# RP2350 register map
Vendor: Raspberry Pi; File version: 0.1
CPU: CM33 r1p0, little endian, MPU, FPU, VTOR, 4 interrupt priority bits, 54 interrupts, 8 SAU regions
Registers are 32-bit, read-write, reset 0x0 unless marked. A register's access mark holds for its fields unless they carry their own. Offsets are from the block's base; [hi:lo] are bit positions; {n}, {i} and the like mark numbered series; 'fields as' and 'values as' point back to an identical list.

## TICKS
Base 0x40108000
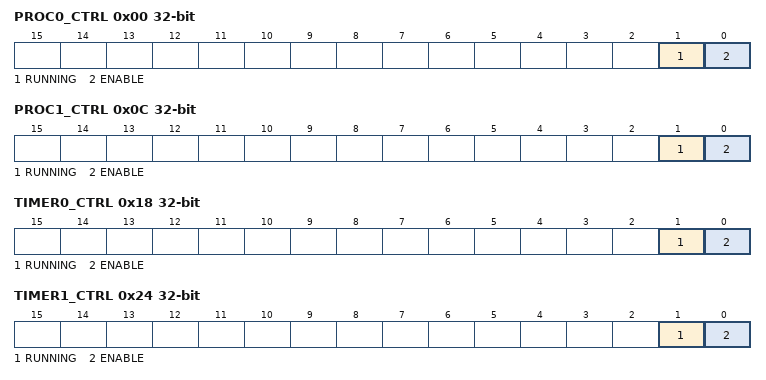
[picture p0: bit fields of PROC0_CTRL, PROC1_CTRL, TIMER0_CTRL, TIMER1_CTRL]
0x00 PROC0_CTRL access per field — Controls the tick generator
  [1] RUNNING ro — Is the tick generator running?
  [0] ENABLE rw — start / stop tick generation
0x04 PROC0_CYCLES
  [8:0] PROC0_CYCLES — Total number of clk_tick cycles before the next tick.
0x08 PROC0_COUNT ro
  [8:0] PROC0_COUNT — Count down timer: the remaining number clk_tick cycles before the next tick is generated.
0x0C PROC1_CTRL access per field — Controls the tick generator
  fields as PROC0_CTRL
0x10 PROC1_CYCLES
  [8:0] PROC1_CYCLES — Total number of clk_tick cycles before the next tick.
0x14 PROC1_COUNT ro
  [8:0] PROC1_COUNT — Count down timer: the remaining number clk_tick cycles before the next tick is generated.
0x18 TIMER0_CTRL access per field — Controls the tick generator
  fields as PROC0_CTRL
0x1C TIMER0_CYCLES
  [8:0] TIMER0_CYCLES — Total number of clk_tick cycles before the next tick.
0x20 TIMER0_COUNT ro
  [8:0] TIMER0_COUNT — Count down timer: the remaining number clk_tick cycles before the next tick is generated.
0x24 TIMER1_CTRL access per field — Controls the tick generator
  fields as PROC0_CTRL
0x28 TIMER1_CYCLES
  [8:0] TIMER1_CYCLES — Total number of clk_tick cycles before the next tick.
0x2C TIMER1_COUNT ro
  [8:0] TIMER1_COUNT — Count down timer: the remaining number clk_tick cycles before the next tick is generated.
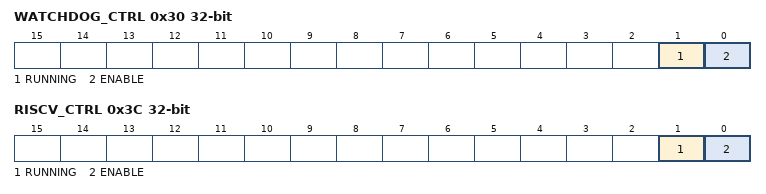
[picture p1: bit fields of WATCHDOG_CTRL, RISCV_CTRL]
0x30 WATCHDOG_CTRL access per field — Controls the tick generator
  fields as PROC0_CTRL
0x34 WATCHDOG_CYCLES
  [8:0] WATCHDOG_CYCLES — Total number of clk_tick cycles before the next tick.
0x38 WATCHDOG_COUNT ro
  [8:0] WATCHDOG_COUNT — Count down timer: the remaining number clk_tick cycles before the next tick is generated.
0x3C RISCV_CTRL access per field — Controls the tick generator
  fields as PROC0_CTRL
0x40 RISCV_CYCLES
  [8:0] RISCV_CYCLES — Total number of clk_tick cycles before the next tick.
0x44 RISCV_COUNT ro
  [8:0] RISCV_COUNT — Count down timer: the remaining number clk_tick cycles before the next tick is generated.

## GLITCH_DETECTOR — Glitch detector controls
Base 0x40158000
0x00 ARM reset 0x5BAD — Forcibly arm the glitch detectors, if they are not already armed by OTP. When armed, any individual detector trigger will cause a restart of the switched core power domain's power-on reset state machine. . Glitch detector triggers are recorded accumulatively in TRIG_STATUS. If the system is reset by a glitch detector trigger, this is recorded in POWMAN_CHIP_RESET. . This register is Secure read/write only.
  [15:0] ARM
    0x5BAD=no (Do not force the glitch detectors to be armed); 0=yes (Force the glitch detectors to be armed. (Any value other than ARM_NO counts as YES))
0x04 DISARM
  [15:0] DISARM — Forcibly disarm the glitch detectors, if they are armed by OTP. Ignored if ARM is YES. . This register is Secure read/write only.
    0=no (Do not disarm the glitch detectors. (Any value other than DISARM_YES counts as NO)); 0xDCAF=yes (Disarm the glitch detectors)
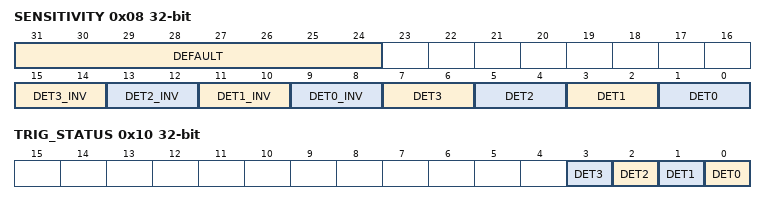
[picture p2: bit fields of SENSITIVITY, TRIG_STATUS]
0x08 SENSITIVITY — Adjust the sensitivity of glitch detectors to values other than their OTP-provided defaults. . This register is Secure read/write only.
  [31:24] DEFAULT
    0=yes (Use the default sensitivity configured in OTP for all detectors. (Any value other than DEFAULT_NO counts as YES)); 222=no (Do not use the default sensitivity configured in OTP. Instead use the value from this register.)
  [2n+9:2n+8] DET{n}_INV (n=0..3) — Must be the inverse of DET{n}, else the default value is used.
  [2n+1:2n] DET{n} (n=0..3) — Set sensitivity for detector {n}. Higher values are more sensitive.
0x0C LOCK
  [7:0] LOCK — Write any nonzero value to disable writes to ARM, DISARM, SENSITIVITY and LOCK. This register is Secure read/write only.
0x10 TRIG_STATUS — Set when a detector output triggers. Write-1-clear. (May immediately return high if the detector remains in a failed state. Detectors can only be cleared by a full reset of the switched core power domain.) . This register is Secure read/write only.
  [n] DET{n} write-1-clears (n=0..3)
0x14 TRIG_FORCE — Simulate the firing of one or more detectors. Writing ones to this register will set the matching bits in STATUS_TRIG. . If the glitch detectors are currently armed, writing ones will also immediately reset the switched core power domain, and set the reset reason latches in POWMAN_CHIP_RESET to indicate a glitch detector resets. . This register is Secure read/write only.
  [3:0] TRIG_FORCE write-clears
